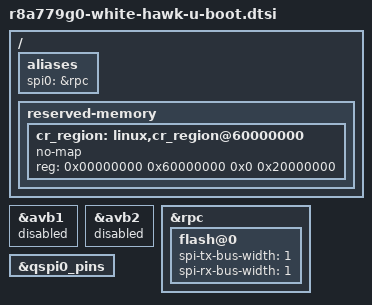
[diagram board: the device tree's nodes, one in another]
// SPDX-License-Identifier: GPL-2.0
/*
 * Device Tree Source extras for U-Boot for the White Hawk board
 *
 * Copyright (C) 2021 Renesas Electronics Corp.
 */

#include "r8a779g0-u-boot.dtsi"

/ {
	aliases {
		spi0 = &rpc;
	};

	reserved-memory {
		#address-cells = <2>;
		#size-cells = <2>;
		ranges;

		cr_region: linux,cr_region@60000000 {
			no-map;
			reg = <0x00000000 0x60000000 0x0 0x20000000>;
		};
	};
};

&avb1 {
	status = "disabled";
};

&avb2 {
	status = "disabled";
};

&rpc {
	bootph-all;
	flash@0 {
		bootph-all;
		spi-tx-bus-width = <1>;
		spi-rx-bus-width = <1>;
	};
};

&qspi0_pins {
	bootph-all;
};
